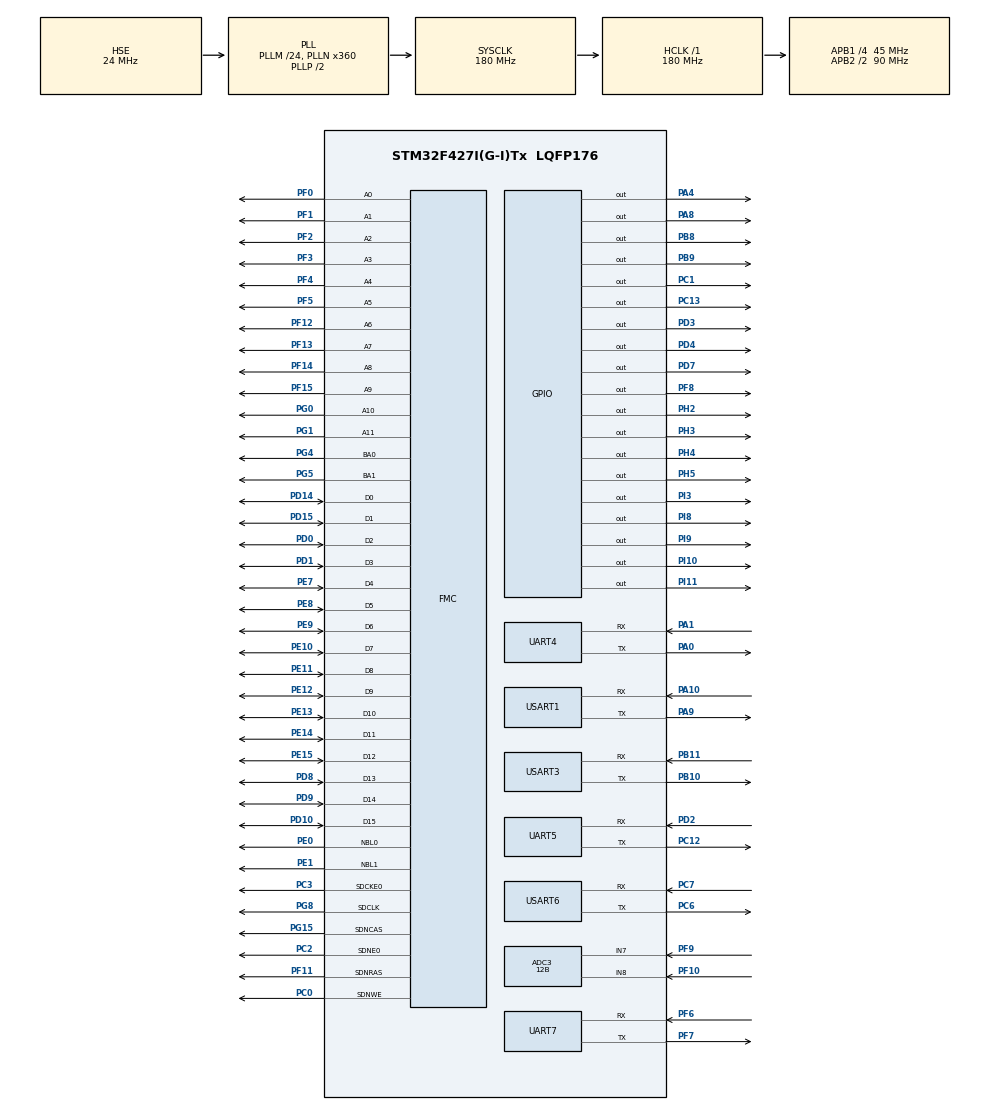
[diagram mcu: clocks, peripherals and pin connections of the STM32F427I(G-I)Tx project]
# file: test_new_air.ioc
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ADC3.Channel-0\#ChannelRegularConversion=ADC_CHANNEL_7
ADC3.ClockPrescaler=ADC_CLOCK_SYNC_PCLK_DIV4
ADC3.ContinuousConvMode=DISABLE
ADC3.DMAContinuousRequests=DISABLE
ADC3.DataAlign=ADC_DATAALIGN_RIGHT
ADC3.DiscontinuousConvMode=DISABLE
ADC3.EOCSelection=ADC_EOC_SINGLE_CONV
ADC3.EnableAnalogWatchDog=false
ADC3.ExternalTrigConv=ADC_SOFTWARE_START
ADC3.ExternalTrigConvEdge=ADC_EXTERNALTRIGCONVEDGE_NONE
ADC3.InjNumberOfConversion=0
ADC3.NbrOfConversion=1
ADC3.NbrOfConversionFlag=1
ADC3.Rank-0\#ChannelRegularConversion=1
ADC3.Resolution=ADC_RESOLUTION_12B
ADC3.SamplingTime-0\#ChannelRegularConversion=ADC_SAMPLETIME_3CYCLES
ADC3.ScanConvMode=DISABLE
Dma.Request0=USART3_TX
Dma.Request1=USART3_RX
Dma.Request2=UART5_RX
Dma.Request3=UART5_TX
Dma.Request4=USART6_RX
Dma.Request5=USART6_TX
Dma.Request6=UART4_RX
Dma.Request7=UART4_TX
Dma.UART4_RX.6.Direction=DMA_PERIPH_TO_MEMORY
Dma.UART4_RX.6.FIFOMode=DMA_FIFOMODE_DISABLE
Dma.UART4_RX.6.Instance=DMA1_Stream2
Dma.UART4_RX.6.MemDataAlignment=DMA_MDATAALIGN_BYTE
Dma.UART4_RX.6.MemInc=DMA_MINC_ENABLE
Dma.UART4_RX.6.Mode=DMA_CIRCULAR
Dma.UART4_RX.6.PeriphDataAlignment=DMA_PDATAALIGN_BYTE
Dma.UART4_RX.6.PeriphInc=DMA_PINC_DISABLE
Dma.UART4_RX.6.Priority=DMA_PRIORITY_MEDIUM
Dma.UART4_TX.7.Direction=DMA_MEMORY_TO_PERIPH
Dma.UART4_TX.7.FIFOMode=DMA_FIFOMODE_DISABLE
Dma.UART4_TX.7.Instance=DMA1_Stream4
Dma.UART4_TX.7.MemDataAlignment=DMA_MDATAALIGN_BYTE
Dma.UART4_TX.7.MemInc=DMA_MINC_ENABLE
Dma.UART4_TX.7.Mode=DMA_NORMAL
Dma.UART4_TX.7.PeriphDataAlignment=DMA_PDATAALIGN_BYTE
Dma.UART4_TX.7.PeriphInc=DMA_PINC_DISABLE
Dma.UART4_TX.7.Priority=DMA_PRIORITY_MEDIUM
Dma.UART5_RX.2.Direction=DMA_PERIPH_TO_MEMORY
Dma.UART5_RX.2.FIFOMode=DMA_FIFOMODE_DISABLE
Dma.UART5_RX.2.Instance=DMA1_Stream0
Dma.UART5_RX.2.MemDataAlignment=DMA_MDATAALIGN_BYTE
Dma.UART5_RX.2.MemInc=DMA_MINC_ENABLE
Dma.UART5_RX.2.Mode=DMA_NORMAL
Dma.UART5_RX.2.PeriphDataAlignment=DMA_PDATAALIGN_BYTE
Dma.UART5_RX.2.PeriphInc=DMA_PINC_DISABLE
Dma.UART5_RX.2.Priority=DMA_PRIORITY_MEDIUM
Dma.UART5_TX.3.Direction=DMA_MEMORY_TO_PERIPH
Dma.UART5_TX.3.FIFOMode=DMA_FIFOMODE_DISABLE
Dma.UART5_TX.3.Instance=DMA1_Stream7
Dma.UART5_TX.3.MemDataAlignment=DMA_MDATAALIGN_BYTE
Dma.UART5_TX.3.MemInc=DMA_MINC_ENABLE
Dma.UART5_TX.3.Mode=DMA_NORMAL
Dma.UART5_TX.3.PeriphDataAlignment=DMA_PDATAALIGN_BYTE
Dma.UART5_TX.3.PeriphInc=DMA_PINC_DISABLE
Dma.UART5_TX.3.Priority=DMA_PRIORITY_MEDIUM
Dma.USART3_RX.1.Direction=DMA_PERIPH_TO_MEMORY
Dma.USART3_RX.1.FIFOMode=DMA_FIFOMODE_DISABLE
Dma.USART3_RX.1.Instance=DMA1_Stream1
Dma.USART3_RX.1.MemDataAlignment=DMA_MDATAALIGN_BYTE
Dma.USART3_RX.1.MemInc=DMA_MINC_ENABLE
Dma.USART3_RX.1.Mode=DMA_CIRCULAR
Dma.USART3_RX.1.PeriphDataAlignment=DMA_PDATAALIGN_BYTE
Dma.USART3_RX.1.PeriphInc=DMA_PINC_DISABLE
Dma.USART3_RX.1.Priority=DMA_PRIORITY_MEDIUM
Dma.USART3_TX.0.Direction=DMA_MEMORY_TO_PERIPH
Dma.USART3_TX.0.FIFOMode=DMA_FIFOMODE_DISABLE
Dma.USART3_TX.0.Instance=DMA1_Stream3
Dma.USART3_TX.0.MemDataAlignment=DMA_MDATAALIGN_BYTE
Dma.USART3_TX.0.MemInc=DMA_MINC_ENABLE
Dma.USART3_TX.0.Mode=DMA_NORMAL
Dma.USART3_TX.0.PeriphDataAlignment=DMA_PDATAALIGN_BYTE
Dma.USART3_TX.0.PeriphInc=DMA_PINC_DISABLE
Dma.USART3_TX.0.Priority=DMA_PRIORITY_MEDIUM
Dma.USART6_RX.4.Direction=DMA_PERIPH_TO_MEMORY
Dma.USART6_RX.4.FIFOMode=DMA_FIFOMODE_DISABLE
Dma.USART6_RX.4.Instance=DMA2_Stream1
Dma.USART6_RX.4.MemDataAlignment=DMA_MDATAALIGN_BYTE
Dma.USART6_RX.4.MemInc=DMA_MINC_ENABLE
Dma.USART6_RX.4.Mode=DMA_CIRCULAR
Dma.USART6_RX.4.PeriphDataAlignment=DMA_PDATAALIGN_BYTE
Dma.USART6_RX.4.PeriphInc=DMA_PINC_DISABLE
Dma.USART6_RX.4.Priority=DMA_PRIORITY_LOW
Dma.USART6_TX.5.Direction=DMA_MEMORY_TO_PERIPH
Dma.USART6_TX.5.FIFOMode=DMA_FIFOMODE_DISABLE
Dma.USART6_TX.5.Instance=DMA2_Stream6
Dma.USART6_TX.5.MemDataAlignment=DMA_MDATAALIGN_BYTE
Dma.USART6_TX.5.MemInc=DMA_MINC_ENABLE
Dma.USART6_TX.5.Mode=DMA_NORMAL
Dma.USART6_TX.5.PeriphDataAlignment=DMA_PDATAALIGN_BYTE
Dma.USART6_TX.5.PeriphInc=DMA_PINC_DISABLE
Dma.USART6_TX.5.Priority=DMA_PRIORITY_LOW
FMC.CASLatency2=FMC_SDRAM_CAS_LATENCY_2
FMC.ExitSelfRefreshDelay2=7
FMC.LoadToActiveDelay2=2
FMC.RCDDelay2=2
FMC.RPDelay1=5
FMC.RPDelay2=5
FMC.RowCycleDelay1=7
FMC.RowCycleDelay2=7
FMC.SDClockPeriod1=FMC_SDRAM_CLOCK_PERIOD_2
FMC.SDClockPeriod2=FMC_SDRAM_CLOCK_PERIOD_2
FMC.SelfRefreshTime2=4
FMC.WriteRecoveryTime2=3
Mcu.Family=STM32F4
Mcu.Name=STM32F427I(G-I)Tx
Mcu.Package=LQFP176
NVIC.DMA1_Stream0_IRQn=true\:0\:0\:false\:false\:true\:false
NVIC.DMA1_Stream1_IRQn=true\:0\:0\:false\:false\:true\:false
NVIC.DMA1_Stream2_IRQn=true\:0\:0\:false\:false\:true\:false
NVIC.DMA1_Stream3_IRQn=true\:0\:0\:false\:false\:true\:false
NVIC.DMA1_Stream4_IRQn=true\:0\:0\:false\:false\:true\:false
NVIC.DMA1_Stream7_IRQn=true\:0\:0\:false\:false\:true\:false
NVIC.DMA2_Stream1_IRQn=true\:0\:0\:false\:true\:true\:2\:false
NVIC.DMA2_Stream6_IRQn=true\:0\:0\:false\:true\:true\:3\:false
NVIC.PriorityGroup=NVIC_PRIORITYGROUP_4
NVIC.UART4_IRQn=true\:0\:0\:false\:false\:true\:true
NVIC.UART5_IRQn=true\:0\:0\:false\:false\:true\:true
NVIC.USART1_IRQn=true\:0\:0\:false\:false\:true\:true
NVIC.USART3_IRQn=true\:0\:0\:false\:false\:true\:true
NVIC.USART6_IRQn=true\:0\:0\:false\:true\:true\:1\:true
PA0/WKUP.Mode=Asynchronous
PA0/WKUP.Signal=UART4_TX
PA1.Mode=Asynchronous
PA1.Signal=UART4_RX
PA10.Mode=Asynchronous
PA10.Signal=USART1_RX
PA4.Signal=GPIO_Output
PA8.Signal=GPIO_Output
PA9.Mode=Asynchronous
PA9.Signal=USART1_TX
PB10.Mode=Asynchronous
PB10.Signal=USART3_TX
PB11.Mode=Asynchronous
PB11.Signal=USART3_RX
PB8.Signal=GPIO_Output
PB9.Signal=GPIO_Output
PC0.Signal=FMC_SDNWE
PC1.Signal=GPIO_Output
PC12.Mode=Asynchronous
PC12.Signal=UART5_TX
PC13.Signal=GPIO_Output
PC2.Mode=SdramChipSelect1_2
PC2.Signal=FMC_SDNE0
PC3.Mode=SdramChipSelect1_2
PC3.Signal=FMC_SDCKE0
PC6.Mode=Asynchronous
PC6.Signal=USART6_TX
PC7.Mode=Asynchronous
PC7.Signal=USART6_RX
PD0.Signal=FMC_D2_DA2
PD1.Signal=FMC_D3_DA3
PD10.Signal=FMC_D15_DA15
PD14.Signal=FMC_D0_DA0
PD15.Signal=FMC_D1_DA1
PD2.Mode=Asynchronous
PD2.Signal=UART5_RX
PD3.Signal=GPIO_Output
PD4.Signal=GPIO_Output
PD7.Signal=GPIO_Output
PD8.Signal=FMC_D13_DA13
PD9.Signal=FMC_D14_DA14
PE0.Signal=FMC_NBL0
PE1.Signal=FMC_NBL1
PE10.Signal=FMC_D7_DA7
PE11.Signal=FMC_D8_DA8
PE12.Signal=FMC_D9_DA9
PE13.Signal=FMC_D10_DA10
PE14.Signal=FMC_D11_DA11
PE15.Signal=FMC_D12_DA12
PE7.Signal=FMC_D4_DA4
PE8.Signal=FMC_D5_DA5
PE9.Signal=FMC_D6_DA6
PF0.Signal=FMC_A0
PF1.Signal=FMC_A1
PF10.Mode=IN8
PF10.Signal=ADC3_IN8
PF11.Signal=FMC_SDNRAS
PF12.Signal=FMC_A6
PF13.Signal=FMC_A7
PF14.Signal=FMC_A8
PF15.Signal=FMC_A9
PF2.Signal=FMC_A2
PF3.Signal=FMC_A3
PF4.Signal=FMC_A4
PF5.Signal=FMC_A5
PF6.Mode=Asynchronous
PF6.Signal=UART7_RX
PF7.Mode=Asynchronous
PF7.Signal=UART7_TX
PF8.Signal=GPIO_Output
PF9.Mode=IN7
PF9.Signal=ADC3_IN7
PG0.Signal=FMC_A10
PG1.Signal=FMC_A11
PG15.Signal=FMC_SDNCAS
PG4.Signal=FMC_A14_BA0
PG5.Signal=FMC_A15_BA1
PG8.Signal=FMC_SDCLK
PH0/OSC_IN.Mode=HSE-External-Oscillator
PH0/OSC_IN.Signal=RCC_OSC_IN
PH1/OSC_OUT.Mode=HSE-External-Oscillator
PH1/OSC_OUT.Signal=RCC_OSC_OUT
PH2.Signal=GPIO_Output
PH3.Signal=GPIO_Output
PH4.Signal=GPIO_Output
PH5.Signal=GPIO_Output
PI10.Signal=GPIO_Output
PI11.Signal=GPIO_Output
PI3.Signal=GPIO_Output
PI8.Signal=GPIO_Output
PI9.Signal=GPIO_Output
ProjectManager.HeapSize=0x3600
ProjectManager.StackSize=0x1200
ProjectManager.TargetToolchain=MDK-ARM V5
RCC.48MHZClocksFreq_Value=90000000
RCC.AHBFreq_Value=180000000
RCC.APB1CLKDivider=RCC_HCLK_DIV4
RCC.APB1Freq_Value=45000000
RCC.APB1TimFreq_Value=90000000
RCC.APB2CLKDivider=RCC_HCLK_DIV2
RCC.APB2Freq_Value=90000000
RCC.APB2TimFreq_Value=180000000
RCC.CortexFreq_Value=180000000
RCC.HCLKFreq_Value=180000000
RCC.HSE_VALUE=24000000
RCC.HSI_VALUE=16000000
RCC.LSE_VALUE=32768
RCC.PLLM=24
RCC.PLLN=360
RCC.PLLSourceVirtual=RCC_PLLSOURCE_HSE
RCC.SYSCLKFreq_VALUE=180000000
RCC.SYSCLKSource=RCC_SYSCLKSOURCE_PLLCLK
RCC.VCOOutputFreq_Value=360000000
SH.FMC_A0.0=FMC_A0,12b-sda2
SH.FMC_A1.0=FMC_A1,12b-sda2
SH.FMC_A10.0=FMC_A10,12b-sda2
SH.FMC_A11.0=FMC_A11,12b-sda2
SH.FMC_A14_BA0.0=FMC_BA0,FourSdramBanks2
SH.FMC_A15_BA1.0=FMC_BA1,FourSdramBanks2
SH.FMC_A2.0=FMC_A2,12b-sda2
SH.FMC_A3.0=FMC_A3,12b-sda2
SH.FMC_A4.0=FMC_A4,12b-sda2
SH.FMC_A5.0=FMC_A5,12b-sda2
SH.FMC_A6.0=FMC_A6,12b-sda2
SH.FMC_A7.0=FMC_A7,12b-sda2
SH.FMC_A8.0=FMC_A8,12b-sda2
SH.FMC_A9.0=FMC_A9,12b-sda2
SH.FMC_D0_DA0.0=FMC_D0,sd-16b-d2
SH.FMC_D10_DA10.0=FMC_D10,sd-16b-d2
SH.FMC_D11_DA11.0=FMC_D11,sd-16b-d2
SH.FMC_D12_DA12.0=FMC_D12,sd-16b-d2
SH.FMC_D13_DA13.0=FMC_D13,sd-16b-d2
SH.FMC_D14_DA14.0=FMC_D14,sd-16b-d2
SH.FMC_D15_DA15.0=FMC_D15,sd-16b-d2
SH.FMC_D1_DA1.0=FMC_D1,sd-16b-d2
SH.FMC_D2_DA2.0=FMC_D2,sd-16b-d2
SH.FMC_D3_DA3.0=FMC_D3,sd-16b-d2
SH.FMC_D4_DA4.0=FMC_D4,sd-16b-d2
SH.FMC_D5_DA5.0=FMC_D5,sd-16b-d2
SH.FMC_D6_DA6.0=FMC_D6,sd-16b-d2
SH.FMC_D7_DA7.0=FMC_D7,sd-16b-d2
SH.FMC_D8_DA8.0=FMC_D8,sd-16b-d2
SH.FMC_D9_DA9.0=FMC_D9,sd-16b-d2
SH.FMC_NBL0.0=FMC_NBL0,Sd2ByteEnable2
SH.FMC_NBL1.0=FMC_NBL1,Sd2ByteEnable2
SH.FMC_SDCLK.0=FMC_SDCLK,12b-sda2
SH.FMC_SDNCAS.0=FMC_SDNCAS,12b-sda2
SH.FMC_SDNRAS.0=FMC_SDNRAS,12b-sda2
SH.FMC_SDNWE.0=FMC_SDNWE,12b-sda2
UART4.VirtualMode=Asynchronous
UART5.VirtualMode=Asynchronous
UART7.VirtualMode=Asynchronous
USART1.VirtualMode=VM_ASYNC
USART3.VirtualMode=VM_ASYNC
USART6.VirtualMode=VM_ASYNC
board=custom

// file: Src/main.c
/**
  ******************************************************************************
  * @file           : main.c
  * @brief          : Main program body
  ******************************************************************************
  ** This notice applies to any and all portions of this file
  * that are not between comment pairs USER CODE BEGIN and
  * USER CODE END. Other portions of this file, whether
  * inserted by the user or by software development tools
  * are owned by their respective copyright owners.
  *
  * COPYRIGHT(c) 2019 STMicroelectronics
  *
  * Redistribution and use in source and binary forms, with or without modification,
  * are permitted provided that the following conditions are met:
  *   1. Redistributions of source code must retain the above copyright notice,
  *      this list of conditions and the following disclaimer.
  *   2. Redistributions in binary form must reproduce the above copyright notice,
  *      this list of conditions and the following disclaimer in the documentation
  *      and/or other materials provided with the distribution.
  *   3. Neither the name of STMicroelectronics nor the names of its contributors
  *      may be used to endorse or promote products derived from this software
  *      without specific prior written permission.
  *
  * THIS SOFTWARE IS PROVIDED BY THE COPYRIGHT HOLDERS AND CONTRIBUTORS "AS IS"
  * AND ANY EXPRESS OR IMPLIED WARRANTIES, INCLUDING, BUT NOT LIMITED TO, THE
  * IMPLIED WARRANTIES OF MERCHANTABILITY AND FITNESS FOR A PARTICULAR PURPOSE ARE
  * DISCLAIMED. IN NO EVENT SHALL THE COPYRIGHT HOLDER OR CONTRIBUTORS BE LIABLE
  * FOR ANY DIRECT, INDIRECT, INCIDENTAL, SPECIAL, EXEMPLARY, OR CONSEQUENTIAL
  * DAMAGES (INCLUDING, BUT NOT LIMITED TO, PROCUREMENT OF SUBSTITUTE GOODS OR
  * SERVICES; LOSS OF USE, DATA, OR PROFITS; OR BUSINESS INTERRUPTION) HOWEVER
  * CAUSED AND ON ANY THEORY OF LIABILITY, WHETHER IN CONTRACT, STRICT LIABILITY,
  * OR TORT (INCLUDING NEGLIGENCE OR OTHERWISE) ARISING IN ANY WAY OUT OF THE USE
  * OF THIS SOFTWARE, EVEN IF ADVISED OF THE POSSIBILITY OF SUCH DAMAGE.
  *
  ******************************************************************************
  */
#include "main.h"
#include "stm32f4xx_hal.h"
#include "adc.h"
#include "dma.h"
#include "usart.h"
#include "gpio.h"
#include "fmc.h"

/* USER CODE BEGIN Includes */
#include "string.h"
/* USER CODE END Includes */

/* USER CODE BEGIN PV */
/* Private variables ---------------------------------------------------------*/
uint8_t buffer[100];
static char buffer_test[15] = "hello...\r\n";
char buffer_test1[10] = "test1...\r\n";
/* USER CODE END PV */

void SystemClock_Config(void);
static void MX_NVIC_Init(void);

/* USER CODE BEGIN PFP */
/* Private function prototypes -----------------------------------------------*/

/* USER CODE END PFP */

int main(void)
{
  /* USER CODE BEGIN 1 */
   uint8_t test_1 = 0;
  uint8_t len;
  /* USER CODE END 1 */

  /* MCU Configuration----------------------------------------------------------*/

  /* Reset of all peripherals, Initializes the Flash interface and the Systick. */
  HAL_Init();

  /* Configure the system clock */
  SystemClock_Config();

  /* Initialize all configured peripherals */
  MX_GPIO_Init();
  MX_DMA_Init();
  MX_USART3_UART_Init();
  MX_USART1_UART_Init();
  MX_UART4_Init();
  MX_ADC3_Init();
  MX_UART5_Init();
  MX_UART7_Init();
  MX_USART6_UART_Init();
  MX_FMC_Init();

  /* Initialize interrupts */
  MX_NVIC_Init();
  /* USER CODE BEGIN 2 */

    HAL_GPIO_WritePin(GPIOB,GPIO_PIN_9,GPIO_PIN_SET);  //this is 485_EN_1
    HAL_GPIO_WritePin(GPIOB,GPIO_PIN_8,GPIO_PIN_SET);  //this is 485_EN_2
    HAL_GPIO_WritePin(GPIOD,GPIO_PIN_3,GPIO_PIN_SET);  //this is 485_EN_3
    HAL_GPIO_WritePin(GPIOD,GPIO_PIN_4,GPIO_PIN_SET);  //this is 485_EN_4
    HAL_GPIO_WritePin(GPIOD,GPIO_PIN_7,GPIO_PIN_SET);  //this is 485_EN_5
    HAL_GPIO_WritePin(GPIOI,GPIO_PIN_3,GPIO_PIN_SET);  //this is 485_EN_6
    HAL_GPIO_WritePin(GPIOA,GPIO_PIN_8,GPIO_PIN_SET);  //this is 485_EN_7

   char buf[10] = "init...\r\n";
   HAL_UART_Transmit(&huart5, buf, strlen((const char *)buf), 10);
   HAL_UART_Receive_DMA(&huart3, buffer, 10);
   sdram_init_sequence(&hsdram2);
  /* USER CODE END 2 */

  /* Infinite loop */
  while (1)
  {

  /* USER CODE BEGIN 3 */

//   HAL_UART_Transmit_DMA(&huart5,buffer_test1,strlen((const char *)buffer_test));
//   HAL_Delay(500);

   * (uint8_t *)(0xC0000000) = 9;
   test_1 = *(uint8_t *)0xC0000000;
   len = sprintf(buffer_test,"---test_1= %d--------\r\n",test_1);

   HAL_UART_Transmit_DMA(&huart5, buffer_test, len);
   HAL_Delay(1000);

  }
  /* USER CODE END 3 */

}

void SystemClock_Config(void)
{

  RCC_OscInitTypeDef RCC_OscInitStruct;
  RCC_ClkInitTypeDef RCC_ClkInitStruct;

    /**Configure the main internal regulator output voltage
    */
  __HAL_RCC_PWR_CLK_ENABLE();

  __HAL_PWR_VOLTAGESCALING_CONFIG(PWR_REGULATOR_VOLTAGE_SCALE1);

    /**Initializes the CPU, AHB and APB busses clocks
    */
  RCC_OscInitStruct.OscillatorType = RCC_OSCILLATORTYPE_HSE;
  RCC_OscInitStruct.HSEState = RCC_HSE_ON;
  RCC_OscInitStruct.PLL.PLLState = RCC_PLL_ON;
  RCC_OscInitStruct.PLL.PLLSource = RCC_PLLSOURCE_HSE;
  RCC_OscInitStruct.PLL.PLLM = 24;
  RCC_OscInitStruct.PLL.PLLN = 360;
  RCC_OscInitStruct.PLL.PLLP = RCC_PLLP_DIV2;
  RCC_OscInitStruct.PLL.PLLQ = 4;
  if (HAL_RCC_OscConfig(&RCC_OscInitStruct) != HAL_OK)
  {
    _Error_Handler(__FILE__, __LINE__);
  }

    /**Activate the Over-Drive mode
    */
  if (HAL_PWREx_EnableOverDrive() != HAL_OK)
  {
    _Error_Handler(__FILE__, __LINE__);
  }

    /**Initializes the CPU, AHB and APB busses clocks
    */
  RCC_ClkInitStruct.ClockType = RCC_CLOCKTYPE_HCLK|RCC_CLOCKTYPE_SYSCLK
                              |RCC_CLOCKTYPE_PCLK1|RCC_CLOCKTYPE_PCLK2;
  RCC_ClkInitStruct.SYSCLKSource = RCC_SYSCLKSOURCE_PLLCLK;
  RCC_ClkInitStruct.AHBCLKDivider = RCC_SYSCLK_DIV1;
  RCC_ClkInitStruct.APB1CLKDivider = RCC_HCLK_DIV4;
  RCC_ClkInitStruct.APB2CLKDivider = RCC_HCLK_DIV2;

  if (HAL_RCC_ClockConfig(&RCC_ClkInitStruct, FLASH_LATENCY_5) != HAL_OK)
  {
    _Error_Handler(__FILE__, __LINE__);
  }

    /**Configure the Systick interrupt time
    */
  HAL_SYSTICK_Config(HAL_RCC_GetHCLKFreq()/1000);

    /**Configure the Systick
    */
  HAL_SYSTICK_CLKSourceConfig(SYSTICK_CLKSOURCE_HCLK);

  /* SysTick_IRQn interrupt configuration */
  HAL_NVIC_SetPriority(SysTick_IRQn, 0, 0);
}

/**
  * @brief NVIC Configuration.
  * @retval None
  */
static void MX_NVIC_Init(void)
{
  /* USART6_IRQn interrupt configuration */
  HAL_NVIC_SetPriority(USART6_IRQn, 0, 0);
  HAL_NVIC_EnableIRQ(USART6_IRQn);
  /* DMA2_Stream1_IRQn interrupt configuration */
  HAL_NVIC_SetPriority(DMA2_Stream1_IRQn, 0, 0);
  HAL_NVIC_EnableIRQ(DMA2_Stream1_IRQn);
  /* DMA2_Stream6_IRQn interrupt configuration */
  HAL_NVIC_SetPriority(DMA2_Stream6_IRQn, 0, 0);
  HAL_NVIC_EnableIRQ(DMA2_Stream6_IRQn);
}

void _Error_Handler(char *file, int line)
{
  while(1)
  {
  }
}

/************************ (C) COPYRIGHT STMicroelectronics *****END OF FILE****/
